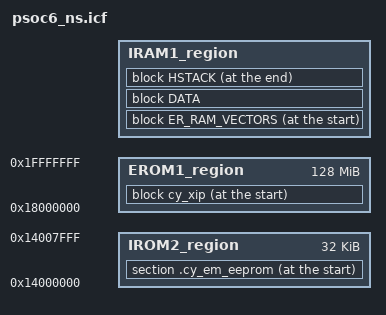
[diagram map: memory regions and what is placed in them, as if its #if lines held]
/*
 * Copyright (c) 2020 Arm Limited
 * Copyright (c) 2020-2021 IAR Systems AB
 * Copyright (c) 2021-2022 Cypress Semiconductor Corporation (an Infineon company)
 * or an affiliate of Cypress Semiconductor Corporation. All rights reserved.
 *
 * Licensed under the Apache License, Version 2.0 (the "License");
 * you may not use this file except in compliance with the License.
 * You may obtain a copy of the License at
 *
 *     http://www.apache.org/licenses/LICENSE-2.0
 *
 * Unless required by applicable law or agreed to in writing, software
 * distributed under the License is distributed on an "AS IS" BASIS,
 * WITHOUT WARRANTIES OR CONDITIONS OF ANY KIND, either express or implied.
 * See the License for the specific language governing permissions and
 * limitations under the License.
 *
 *
 * This file is derivative of ../armclang/psoc6_ns.sct
 */

#include "region_defs.h"

/* The symbols below define the location and size of blocks of memory in the target.
 * Use these symbols to specify the memory regions available for allocation.
 */
/* RAM */
define symbol __ICFEDIT_region_IRAM1_start__ = NS_DATA_START;
define symbol __ICFEDIT_region_IRAM1_end__   = NS_DATA_LIMIT;

/* Flash */
define symbol __ICFEDIT_region_IROM1_start__ = NS_CODE_START;
define symbol __ICFEDIT_region_IROM1_end__   = NS_CODE_LIMIT;

/* The following symbols define a 32K flash region used for EEPROM emulation.
 * This region can also be used as the general purpose flash.
 * You can assign sections to this memory region for only one of the cores.
 * Note some middleware (e.g. BLE, Emulated EEPROM) can place their data into this memory region.
 * Therefore, repurposing this memory region will prevent such middleware from operation.
 */
define symbol __ICFEDIT_region_IROM2_start__ = 0x14000000;
define symbol __ICFEDIT_region_IROM2_end__   = 0x14007FFF;

/* The following symbols define device specific memory regions and must not be changed. */
/* XIP */
define symbol __ICFEDIT_region_EROM1_start__ = 0x18000000;
define symbol __ICFEDIT_region_EROM1_end__   = 0x1FFFFFFF;

define symbol __ICFEDIT_size_proc_stack__ = 0x0;

define memory mem with size = 4G;
define region IROM1_region = mem:[from __ICFEDIT_region_IROM1_start__ to __ICFEDIT_region_IROM1_end__];
define region IROM2_region = mem:[from __ICFEDIT_region_IROM2_start__ to __ICFEDIT_region_IROM2_end__];
define region EROM1_region = mem:[from __ICFEDIT_region_EROM1_start__ to __ICFEDIT_region_EROM1_end__];
define region IRAM1_region = mem:[from __ICFEDIT_region_IRAM1_start__ to __ICFEDIT_region_IRAM1_end__];

define block ER_CODE            with fixed order, alignment = 8 {
       section .intvec,
       readonly};
define block LR_CODE with fixed order, maximum size = NS_CODE_SIZE {block ER_CODE};
place at address NS_CODE_START {block LR_CODE};

define block ER_DATA with alignment = 8 {readwrite};
#ifdef RAM_VECTORS_SUPPORT
define block ER_RAM_VECTORS     with alignment = 256 { section .intvec_ram };
#endif
define block TFM_RAM_CODE       with alignment = 32 { readonly section S_RAM_CODE_SEC_NAME };

define block CSTACK             with alignment = 8, size = NS_MSP_STACK_SIZE { };
define block PROC_STACK         with alignment = 8, size = __ICFEDIT_size_proc_stack__ { };
define block HEAP               with expanding size, alignment = 8, minimum size = NS_HEAP_SIZE { };
define block HSTACK {block HEAP, block PROC_STACK, last block CSTACK};

define block cy_xip { section .cy_xip };

initialize by copy { readwrite };
do not initialize  {
   section .noinit,
   rw section .intvec_ram
   };
if (isdefinedsymbol(__USE_DLIB_PERTHREAD))
{
  // Required in a multi-threaded application
  initialize by copy with packing = none { section __DLIB_PERTHREAD };
}

define block DATA with fixed order, maximum size = NS_DATA_SIZE {
       block TFM_RAM_CODE,
       block ER_DATA,
};

#if defined(PSA_API_TEST_ENABLED)
define region PSA_NVMEM_region = mem:[from PSA_API_TEST_NVMEM_START size PSA_API_TEST_NVMEM_SIZE];
#endif

/* Used for the digital signature of the secure application and the Bootloader SDK application. */
".cy_app_signature" : place at address (__ICFEDIT_region_IROM1_end__ - 0x200) { section .cy_app_signature };

/* Emulated EEPROM Flash area */
".cy_em_eeprom" : place at start of IROM2_region  { section .cy_em_eeprom };

/* Execute in Place (XIP). See the smif driver documentation for details. */
"cy_xip" : place at start of EROM1_region  { block cy_xip };

/* RAM */
#ifdef RAM_VECTORS_SUPPORT
place at start of IRAM1_region  { block ER_RAM_VECTORS };
#endif
place in          IRAM1_region  { block DATA };
place at end   of IRAM1_region  { block HSTACK };

keep {  section .cy_app_signature,
        section .cy_em_eeprom,
        section .cy_xip,
        block CSTACK,
        block HEAP,
        block TFM_RAM_CODE,
         };
